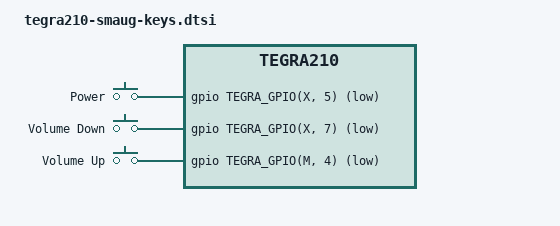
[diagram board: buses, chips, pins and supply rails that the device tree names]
/*
 * Copyright (c) 2015-2016, NVIDIA CORPORATION.  All rights reserved.
 *
 * This program is free software; you can redistribute it and/or modify
 * it under the terms of the GNU General Public License as published by
 * the Free Software Foundation; version 2 of the License.
 *
 * This program is distributed in the hope that it will be useful, but WITHOUT
 * ANY WARRANTY; without even the implied warranty of MERCHANTABILITY or
 * FITNESS FOR A PARTICULAR PURPOSE.  See the GNU General Public License for
 * more details.
 *
 */
#include <dt-bindings/gpio/tegra-gpio.h>
#include <dt-bindings/input/input.h>
#include <dt-bindings/soc/tegra-pmc.h>

/ {
	gpio-keys {
		compatible = "gpio-keys";
		gpio-keys,name = "gpio-keys";

		status = "okay";

		power {
			label = "Power";
			gpios = <&gpio TEGRA_GPIO(X, 5) GPIO_ACTIVE_LOW>;
			linux,code = <KEY_POWER>;
			debounce-interval = <30>;
			wakeup-source;
		};

/*		lid {
			label = "Lid";
			gpios = <&gpio TEGRA_GPIO(B, 4) GPIO_ACTIVE_LOW>;
			linux,input-type = <EV_SW>;
			linux,code = <SW_LID>;
			wakeup-source;
		};

		tablet_mode {
			label = "Tablet Mode";
			gpios = <&gpio TEGRA_GPIO(Z, 2) GPIO_ACTIVE_HIGH>;
			linux,input-type = <EV_SW>;
			linux,code = <SW_TABLET_MODE>;
			wakeup-source;
		};
*/
		volume_down {
			label = "Volume Down";
			gpios = <&gpio TEGRA_GPIO(X, 7) GPIO_ACTIVE_LOW>;
			linux,code = <KEY_VOLUMEDOWN>;
			wakeup-source;
		};

		volume_up {
			label = "Volume Up";
			gpios = <&gpio TEGRA_GPIO(M, 4) GPIO_ACTIVE_LOW>;
			linux,code = <KEY_VOLUMEUP>;
			wakeup-source;
		};
	};

};
